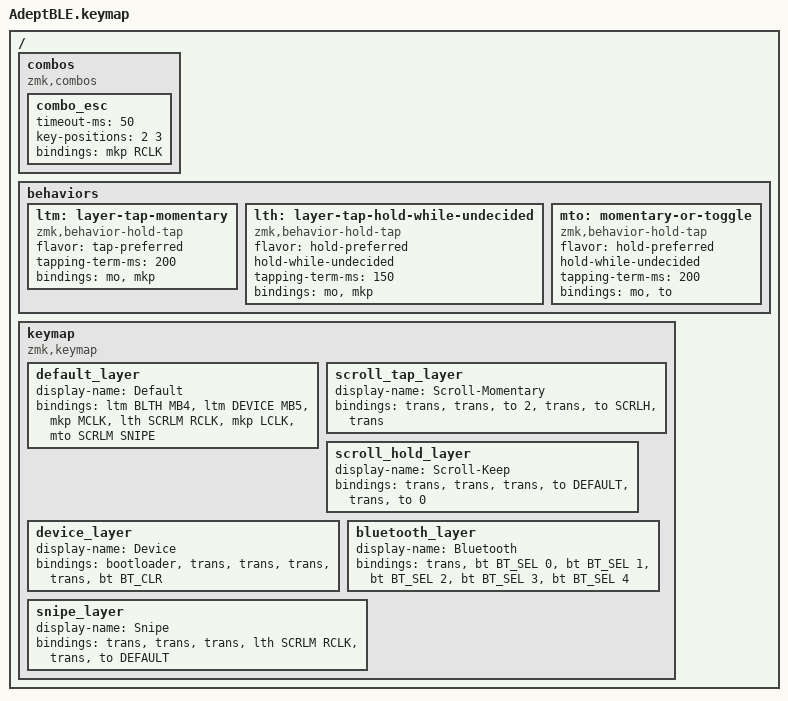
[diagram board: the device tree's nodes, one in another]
#include <behaviors.dtsi>
#include <dt-bindings/zmk/bt.h>
#include <dt-bindings/zmk/pointing.h>

// #include <dt-bindings/zmk/mouse.h>

#define DEFAULT 0
#define SCRLM 1
#define SCRLH 2
#define DEVICE 3
#define BLTH 4
#define SNIPE 5

/ {
    combos {
        compatible = "zmk,combos";

        combo_esc {
            timeout-ms = <50>;
            key-positions = <2 3>;
            bindings = <&mkp RCLK>;
        };
    };

    behaviors {
        ltm: layer-tap-momentary {
            compatible = "zmk,behavior-hold-tap";
            #binding-cells = <2>;
            flavor = "tap-preferred";
            tapping-term-ms = <200>;
            bindings = <&mo>, <&mkp>;
        };

        lth: layer-tap-hold-while-undecided {
            compatible = "zmk,behavior-hold-tap";
            #binding-cells = <2>;
            flavor = "hold-preferred";
            hold-while-undecided;
            tapping-term-ms = <150>;
            bindings = <&mo>, <&mkp>;
        };

        mto: momentary-or-toggle {
            compatible = "zmk,behavior-hold-tap";
            #binding-cells = <2>;
            flavor = "hold-preferred";
            hold-while-undecided;
            tapping-term-ms = <200>;
            bindings = <&mo>, <&to>;
        };
    };

    keymap {
        compatible = "zmk,keymap";

        default_layer {
            display-name = "Default";
            bindings = <
&ltm BLTH MB4  &ltm DEVICE MB5  &mkp MCLK  &lth SCRLM RCLK  &mkp LCLK  &mto SCRLM SNIPE
            >;
        };

        scroll_tap_layer {
            display-name = "Scroll-Momentary";
            bindings = <
&trans  &trans  &to 2  &trans  &to SCRLH  &trans
            >;
        };

        scroll_hold_layer {
            display-name = "Scroll-Keep";
            bindings = <
&trans  &trans  &trans  &to DEFAULT  &trans  &to 0
            >;
        };

        device_layer {
            display-name = "Device";
            bindings = <
&bootloader  &trans  &trans  &trans  &trans  &bt BT_CLR
            >;
        };

        bluetooth_layer {
            display-name = "Bluetooth";
            bindings = <
&trans  &bt BT_SEL 0  &bt BT_SEL 1  &bt BT_SEL 2  &bt BT_SEL 3  &bt BT_SEL 4
            >;
        };

        snipe_layer {
            display-name = "Snipe";
            bindings = <
&trans  &trans  &trans  &lth SCRLM RCLK  &trans  &to DEFAULT
            >;
        };
    };
};
